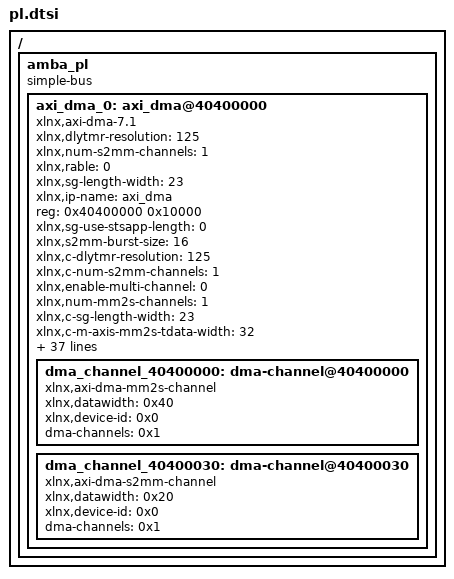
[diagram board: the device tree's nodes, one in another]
/ {
	amba_pl: amba_pl {
		ranges;
		compatible = "simple-bus";
		#address-cells = <1>;
		#size-cells = <1>;
		axi_dma_0: axi_dma@40400000 {
			xlnx,dlytmr-resolution = <125>;
			xlnx,num-s2mm-channels = <1>;
			xlnx,rable = <0>;
			xlnx,sg-length-width = <23>;
			xlnx,ip-name = "axi_dma";
			reg = <0x40400000 0x10000>;
			xlnx,sg-use-stsapp-length = <0>;
			xlnx,s2mm-burst-size = <16>;
			xlnx,c-dlytmr-resolution = <125>;
			xlnx,c-num-s2mm-channels = <1>;
			xlnx,enable-multi-channel = <0>;
			xlnx,num-mm2s-channels = <1>;
			xlnx,c-sg-length-width = <23>;
			compatible = "xlnx,axi-dma-7.1" , "xlnx,axi-dma-1.00.a";
			xlnx,c-m-axis-mm2s-tdata-width = <32>;
			xlnx,c-sg-use-stsapp-length = <0>;
			xlnx,c-s2mm-burst-size = <16>;
			xlnx,mm2s-burst-size = <16>;
			xlnx,c-enable-multi-channel = <0>;
			xlnx,c-num-mm2s-channels = <1>;
			xlnx,include-s2mm-dre = <0>;
			xlnx,c-mm2s-burst-size = <16>;
			status = "okay";
			xlnx,c-include-s2mm-dre = <0>;
			xlnx,include-mm2s-dre = <0>;
			xlnx,name = "axi_dma_0";
			xlnx,c-include-sg = <0>;
			xlnx,c-m-axi-s2mm-data-width = <64>;
			xlnx,include-s2mm-sf = <1>;
			xlnx,c-include-mm2s-dre = <0>;
			xlnx,include-s2mm = <1>;
			clocks = <&clkc 15>, <&clkc 15>, <&clkc 15>;
			xlnx,addrwidth = <0x20>;
			xlnx,c-m-axi-mm2s-data-width = <64>;
			xlnx,edk-iptype = "PERIPHERAL";
			xlnx,c-include-s2mm-sf = <1>;
			xlnx,include-mm2s-sf = <1>;
			clock-names = "m_axi_mm2s_aclk" , "m_axi_s2mm_aclk" , "s_axi_lite_aclk";
			xlnx,c-include-s2mm = <1>;
			xlnx,c-addr-width = <32>;
			xlnx,c-single-interface = <0>;
			xlnx,include-mm2s = <1>;
			xlnx,c-s-axis-s2mm-tdata-width = <32>;
			xlnx,s2mm-data-width = <0x40>;
			xlnx,c-include-mm2s-sf = <1>;
			xlnx,prmry-is-aclk-async = <0>;
			xlnx,c-include-mm2s = <1>;
			xlnx,increase-throughput = <0>;
			xlnx,micro-dma = <0>;
			xlnx,mm2s-data-width = <0x40>;
			xlnx,c-prmry-is-aclk-async = <0>;
			xlnx,c-sg-include-stscntrl-strm = <0>;
			xlnx,c-increase-throughput = <0>;
			xlnx,c-micro-dma = <0>;
			dma_channel_40400000: dma-channel@40400000 {
				xlnx,datawidth = <0x40>;
				xlnx,device-id = <0x0>;
				compatible = "xlnx,axi-dma-mm2s-channel";
				dma-channels = <0x1>;
			};
			dma_channel_40400030: dma-channel@40400030 {
				xlnx,datawidth = <0x20>;
				xlnx,device-id = <0x0>;
				compatible = "xlnx,axi-dma-s2mm-channel";
				dma-channels = <0x1>;
			};
		};
	};
};
